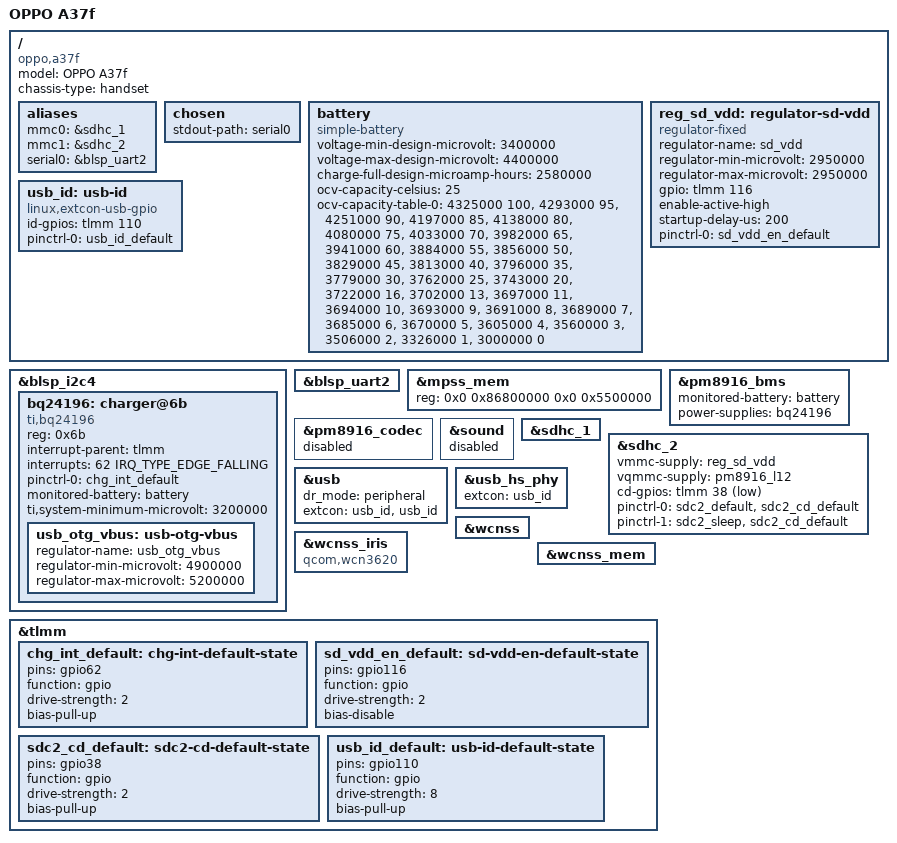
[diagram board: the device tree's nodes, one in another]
// SPDX-License-Identifier: GPL-2.0-only
/dts-v1/;

#include "msm8916-pm8916.dtsi"
#include "msm8916-modem-qdsp6.dtsi"

#include <dt-bindings/gpio/gpio.h>
#include <dt-bindings/interrupt-controller/irq.h>

/ {
	model = "OPPO A37f";
	compatible = "oppo,a37f", "qcom,msm8916";
	chassis-type = "handset";

	aliases {
		mmc0 = &sdhc_1; /* eMMC */
		mmc1 = &sdhc_2; /* SD card */
		serial0 = &blsp_uart2;
	};

	chosen {
		stdout-path = "serial0";
	};

	battery: battery {
		compatible = "simple-battery";
		voltage-min-design-microvolt = <3400000>;
		voltage-max-design-microvolt = <4400000>;
		charge-full-design-microamp-hours = <2580000>;

		ocv-capacity-celsius = <25>;
		ocv-capacity-table-0 = <4325000 100>, <4293000 95>, <4251000 90>,
			<4197000 85>, <4138000 80>, <4080000 75>,
			<4033000 70>, <3982000 65>, <3941000 60>,
			<3884000 55>, <3856000 50>, <3829000 45>,
			<3813000 40>, <3796000 35>, <3779000 30>,
			<3762000 25>, <3743000 20>, <3722000 16>,
			<3702000 13>, <3697000 11>, <3694000 10>,
			<3693000 9>, <3691000 8>, <3689000 7>,
			<3685000 6>, <3670000 5>, <3605000 4>,
			<3560000 3>, <3506000 2>, <3326000 1>,
			<3000000 0>;
	};

	reg_sd_vdd: regulator-sd-vdd {
		compatible = "regulator-fixed";
		regulator-name = "sd_vdd";

		regulator-min-microvolt = <2950000>;
		regulator-max-microvolt = <2950000>;

		gpio = <&tlmm 116 GPIO_ACTIVE_HIGH>;
		enable-active-high;
		startup-delay-us = <200>;

		pinctrl-names = "default";
		pinctrl-0 = <&sd_vdd_en_default>;
	};

	usb_id: usb-id {
		compatible = "linux,extcon-usb-gpio";
		id-gpios = <&tlmm 110 GPIO_ACTIVE_HIGH>;

		pinctrl-names = "default";
		pinctrl-0 = <&usb_id_default>;
	};
};

&blsp_i2c4 {
	status = "okay";

	bq24196: charger@6b {
		compatible = "ti,bq24196";
		reg = <0x6b>;

		interrupt-parent = <&tlmm>;
		interrupts = <62 IRQ_TYPE_EDGE_FALLING>;

		pinctrl-names = "default";
		pinctrl-0 = <&chg_int_default>;

		monitored-battery = <&battery>;
		ti,system-minimum-microvolt = <3200000>;

		usb_otg_vbus: usb-otg-vbus {
			regulator-name = "usb_otg_vbus";
			regulator-min-microvolt = <4900000>;
			regulator-max-microvolt = <5200000>;
		};
	};
};

&blsp_uart2 {
	status = "okay";
};

&mpss_mem {
	reg = <0x0 0x86800000 0x0 0x5500000>;
};

&pm8916_bms {
	status = "okay";

	monitored-battery = <&battery>;
	power-supplies = <&bq24196>;
};

&pm8916_codec {
	status = "disabled";
};

&sound {
	status = "disabled";
};

&sdhc_1 {
	status = "okay";
};

&sdhc_2 {
	status = "okay";

	vmmc-supply = <&reg_sd_vdd>;
	vqmmc-supply = <&pm8916_l12>;

	cd-gpios = <&tlmm 38 GPIO_ACTIVE_LOW>;

	pinctrl-names = "default", "sleep";
	pinctrl-0 = <&sdc2_default &sdc2_cd_default>;
	pinctrl-1 = <&sdc2_sleep &sdc2_cd_default>;
};

&usb {
	status = "okay";
	dr_mode = "peripheral";
	extcon = <&usb_id>, <&usb_id>;
};

&usb_hs_phy {
	extcon = <&usb_id>;
};

&wcnss {
	status = "okay";
};

&wcnss_iris {
	compatible = "qcom,wcn3620";
};

&wcnss_mem {
	status = "okay";
};

&tlmm {
	chg_int_default: chg-int-default-state {
		pins = "gpio62";
		function = "gpio";

		drive-strength = <2>;
		bias-pull-up;
	};

	sd_vdd_en_default: sd-vdd-en-default-state {
		pins = "gpio116";
		function = "gpio";

		drive-strength = <2>;
		bias-disable;
	};

	sdc2_cd_default: sdc2-cd-default-state {
		pins = "gpio38";
		function = "gpio";

		drive-strength = <2>;
		bias-pull-up;
	};

	usb_id_default: usb-id-default-state {
		pins = "gpio110";
		function = "gpio";

		drive-strength = <8>;
		bias-pull-up;
	};
};
